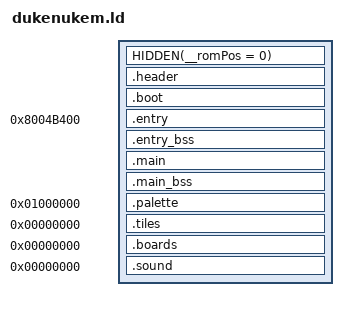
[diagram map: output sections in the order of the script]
SECTIONS
{
    HIDDEN(__romPos = 0);
    header_ROM_START = __romPos;
    header_VRAM = ADDR(.header);
    .header : AT(header_ROM_START) SUBALIGN(16)
    {
        FILL(0x00000000);
        header_DATA_START = .;
        build/header.o(.data);
        header_DATA_END = .;
        header_DATA_SIZE = ABSOLUTE(header_DATA_END - header_DATA_START);
    }
    __romPos += SIZEOF(.header);
    header_ROM_END = __romPos;
    header_VRAM_END = .;

    boot_ROM_START = __romPos;
    boot_VRAM = ADDR(.boot);
    .boot : AT(boot_ROM_START) SUBALIGN(16)
    {
        FILL(0x00000000);
        boot_DATA_START = .;
        build/assets/boot.o(.data);
        boot_DATA_END = .;
        boot_DATA_SIZE = ABSOLUTE(boot_DATA_END - boot_DATA_START);
    }
    __romPos += SIZEOF(.boot);
    boot_ROM_END = __romPos;
    boot_VRAM_END = .;

    entry_ROM_START = __romPos;
    entry_VRAM = ADDR(.entry);
    .entry 0x8004B400 : AT(entry_ROM_START) SUBALIGN(16)
    {
        FILL(0x00000000);
        entry_TEXT_START = .;
        build/src/entry.o(.text);
        . = ALIGN(., 16);
        entry_TEXT_END = .;
        entry_TEXT_SIZE = ABSOLUTE(entry_TEXT_END - entry_TEXT_START);
        entry_DATA_START = .;
        build/src/entry.o(.data);
        . = ALIGN(., 16);
        entry_DATA_END = .;
        entry_DATA_SIZE = ABSOLUTE(entry_DATA_END - entry_DATA_START);
        entry_RODATA_START = .;
        build/src/entry.o(.rodata);
        . = ALIGN(., 16);
        entry_RODATA_END = .;
        entry_RODATA_SIZE = ABSOLUTE(entry_RODATA_END - entry_RODATA_START);
    }
    entry_bss_VRAM = ADDR(.entry_bss);
    .entry_bss (NOLOAD) : SUBALIGN(16)
    {
        FILL(0x00000000);
        entry_BSS_START = .;
        build/src/entry.o(.bss);
        . = ALIGN(., 16);
        entry_BSS_END = .;
        entry_BSS_SIZE = ABSOLUTE(entry_BSS_END - entry_BSS_START);
    }
    __romPos += SIZEOF(.entry);
    __romPos = ALIGN(__romPos, 16);
    . = ALIGN(., 16);
    entry_ROM_END = __romPos;
    entry_VRAM_END = .;

    main_ROM_START = __romPos;
    main_VRAM = ADDR(.main);
    .main entry_VRAM_END : AT(main_ROM_START) SUBALIGN(16)
    {
        FILL(0x00000000);
        main_TEXT_START = .;
        build/src/main.o(.text);
        build/src/sched.o(.text);
        build/asm/control.o(.text);
        build/asm/game1.o(.text);
        build/asm/control2.o(.text);
        build/asm/game2.o(.text);
        build/asm/logo.o(.text);
        build/asm/boss2.o(.text);
        build/asm/sound1.o(.text);
        build/asm/sound2.o(.text);
        build/src/rend1.o(.text);
        build/asm/rend2.o(.text);
        build/src/getangle.o(.text);
        build/src/draw.o(.text);
        build/src/tileinfo.o(.text);
        build/src/rnc.o(.text);
        build/src/display1.o(.text);
        build/src/cache1d.o(.text);
        build/src/display2.o(.text);
        build/src/actors1.o(.text);
        build/src/actors2.o(.text);
        build/src/actors3.o(.text);
        build/src/gamedef.o(.text);
        build/src/script.o(.text);
        build/src/engine.o(.text);
        build/src/game3.o(.text);
        build/src/game4.o(.text);
        build/src/player1.o(.text);
        build/src/player2.o(.text);
        build/src/player3.o(.text);
        build/src/premap.o(.text);
        build/src/sector.o(.text);
        build/src/board.o(.text);
        build/src/tile.o(.text);
        build/src/tables.o(.text);
        build/src/dukebot.o(.text);
        build/asm/menues.o(.text);
        build/src/libultra/io/viblack.o(.text);
        build/src/libultra/os/initialize.o(.text);
        build/src/libultra/os/createthread.o(.text);
        build/src/libultra/os/startthread.o(.text);
        build/src/libultra/io/pimgr.o(.text);
        build/src/libultra/os/setthreadpri.o(.text);
        build/asm/libultra/os/writebackdcacheall.o(.text);
        build/src/libultra/io/pigetstat.o(.text);
        build/src/libultra/io/pidma.o(.text);
        build/src/libultra/os/recvmesg.o(.text);
        build/src/libultra/os/gettime.o(.text);
        build/src/libultra/os/sendmesg.o(.text);
        build/src/libultra/os/createmesgqueue.o(.text);
        build/src/libultra/libc/ll.o(.text);
        build/src/libultra/io/visetyscale.o(.text);
        build/src/libultra/io/vimgr.o(.text);
        build/src/libultra/io/vitbl.o(.text);
        build/asm/libultra/unk1.o(.text);
        build/src/libultra/io/visetmode.o(.text);
        build/src/libultra/io/visetspecial.o(.text);
        build/src/libultra/os/seteventmesg.o(.text);
        build/src/libultra/io/visetevent.o(.text);
        build/asm/libultra/os/setintmask.o(.text);
        build/src/libultra/io/sptaskyielded.o(.text);
        build/src/libultra/io/vigetcurrframebuf.o(.text);
        build/src/libultra/io/vigetnextframebuf.o(.text);
        build/src/libultra/io/viswapbuf.o(.text);
        build/src/libultra/io/sptask.o(.text);
        build/src/libultra/io/dpsetnextbuf.o(.text);
        build/src/libultra/io/sptaskyield.o(.text);
        build/src/libultra/io/contreaddata.o(.text);
        build/src/libultra/io/controller.o(.text);
        build/src/libultra/io/pfsinitpak.o(.text);
        build/src/libultra/io/pfsnumfiles.o(.text);
        build/src/libultra/io/pfsfreeblocks.o(.text);
        build/src/libultra/io/motor.o(.text);
        build/src/libultra/gu/translate.o(.text);
        build/src/libultra/gu/scale.o(.text);
        build/src/libultra/libc/sprintf.o(.text);
        build/src/libultra/libc/string.o(.text);
        build/src/libultra/io/pfsfilestate.o(.text);
        build/src/libultra/os/yieldthread.o(.text);
        build/src/libultra/io/pfsdeletefile.o(.text);
        build/src/libultra/io/pfsallocatefile.o(.text);
        build/src/libultra/io/pfsreadwritefile.o(.text);
        build/src/libultra/io/pfssearchfile.o(.text);
        build/src/libultra/io/pfsrepairid.o(.text);
        build/src/libultra/gu/rotate.o(.text);
        build/src/libultra/os/virtualtophysical.o(.text);
        build/src/libultra/audio/sl.o(.text);
        build/src/libultra/audio/heapalloc.o(.text);
        build/src/libultra/audio/heapinit.o(.text);
        build/src/libultra/io/aisetfreq.o(.text);
        build/src/libultra/audio/sndplayer.o(.text);
        build/src/libultra/audio/bnkf.o(.text);
        build/src/libultra/audio/sndpallocate.o(.text);
        build/src/libultra/audio/csplayer.o(.text);
        build/src/libultra/audio/seqpsetbank.o(.text);
        build/src/libultra/audio/cspsetvol.o(.text);
        build/src/libultra/audio/sndpsetsound.o(.text);
        build/src/libultra/audio/sndpgetstate.o(.text);
        build/src/libultra/audio/sndpsetpitch.o(.text);
        build/src/libultra/audio/sndpsetpan.o(.text);
        build/src/libultra/audio/sndpsetvol.o(.text);
        build/src/libultra/audio/sndpplay.o(.text);
        build/src/libultra/audio/cspstop.o(.text);
        build/src/libultra/audio/cseq.o(.text);
        build/src/libultra/audio/cspsetseq.o(.text);
        build/src/libultra/audio/cspplay.o(.text);
        build/src/libultra/audio/sndpstop.o(.text);
        build/src/libultra/audio/synthesizer.o(.text);
        build/src/libultra/io/aisetnextbuf.o(.text);
        build/src/libultra/gu/sinf.o(.text);
        build/src/libultra/gu/cosf.o(.text);
        build/src/libultra/libc/llcvt.o(.text);
        build/src/libultra/gu/perspective.o(.text);
        build/src/libultra/gu/lookat.o(.text);
        build/src/libultra/gu/lookatref.o(.text);
        build/src/libultra/gu/mtxcatf.o(.text);
        build/asm/libultra/gu/sqrtf.o(.text);
        build/asm/libultra/os/interrupt.o(.text);
        build/src/libultra/io/vi.o(.text);
        build/asm/libultra/os/setsr.o(.text);
        build/asm/libultra/os/getsr.o(.text);
        build/asm/libultra/os/setfpccsr.o(.text);
        build/src/libultra/io/sirawread.o(.text);
        build/src/libultra/io/sirawwrite.o(.text);
        build/asm/libultra/os/exceptasm.o(.text);
        build/asm/libultra/os/writebackdcache.o(.text);
        build/asm/libultra/os/invalicache.o(.text);
        build/asm/libultra/os/maptlbrdb.o(.text);
        build/src/libultra/io/pirawread.o(.text);
        build/asm/libultra/libc/bzero.o(.text);
        build/src/libultra/os/thread.o(.text);
        build/src/libultra/io/cartrominit.o(.text);
        build/src/libultra/io/leodiskinit.o(.text);
        build/src/libultra/io/piacs.o(.text);
        build/src/libultra/os/getthreadpri.o(.text);
        build/src/libultra/io/pirawdma.o(.text);
        build/src/libultra/io/epirawdma.o(.text);
        build/src/libultra/io/devmgr.o(.text);
        build/src/libultra/os/jammesg.o(.text);
        build/src/libultra/io/pigetcmdq.o(.text);
        build/asm/libultra/os/getcount.o(.text);
        build/src/libultra/os/timerintr.o(.text);
        build/src/libultra/io/vigetcurrcontext.o(.text);
        build/src/libultra/io/viswapcontext.o(.text);
        build/src/libultra/io/spgetstat.o(.text);
        build/asm/libultra/libc/bcopy.o(.text);
        build/src/libultra/io/spsetstat.o(.text);
        build/src/libultra/io/spsetpc.o(.text);
        build/src/libultra/io/sprawdma.o(.text);
        build/src/libultra/io/sp.o(.text);
        build/src/libultra/io/dp.o(.text);
        build/src/libultra/io/siacs.o(.text);
        build/src/libultra/io/sirawdma.o(.text);
        build/src/libultra/os/settimer.o(.text);
        build/src/libultra/io/pfsgetstatus.o(.text);
        build/src/libultra/io/contpfs.o(.text);
        build/src/libultra/io/contramread.o(.text);
        build/src/libultra/io/pfschecker.o(.text);
        build/src/libultra/io/pfsisplug.o(.text);
        build/src/libultra/io/crc.o(.text);
        build/src/libultra/io/contramwrite.o(.text);
        build/src/libultra/gu/mtxutil.o(.text);
        build/src/libultra/libc/xprintf.o(.text);
        build/src/libultra/gu/normalize.o(.text);
        build/asm/libultra/os/probetlb.o(.text);
        build/src/libultra/audio/syndelete.o(.text);
        build/src/libultra/audio/event.o(.text);
        build/src/libultra/audio/synaddplayer.o(.text);
        build/src/libultra/audio/synallocvoice.o(.text);
        build/src/libultra/audio/synstartvoice.o(.text);
        build/src/libultra/audio/synsetpan.o(.text);
        build/src/libultra/audio/synsetvol.o(.text);
        build/src/libultra/audio/synsetpitch.o(.text);
        build/src/libultra/audio/synsetfxmix.o(.text);
        build/src/libultra/audio/synstopvoice.o(.text);
        build/src/libultra/audio/synfreevoice.o(.text);
        build/src/libultra/audio/seqplayer.o(.text);
        build/src/libultra/audio/cents2ratio.o(.text);
        build/src/libultra/audio/synstartvoiceparam.o(.text);
        build/src/libultra/audio/drvrNew.o(.text);
        build/src/libultra/audio/synallocfx.o(.text);
        build/src/libultra/audio/mainbus.o(.text);
        build/src/libultra/audio/load.o(.text);
        build/src/libultra/audio/resample.o(.text);
        build/src/libultra/audio/env.o(.text);
        build/src/libultra/audio/auxbus.o(.text);
        build/src/libultra/audio/save.o(.text);
        build/src/libultra/io/ai.o(.text);
        build/src/libultra/io/si.o(.text);
        build/src/libultra/os/kdebugserver.o(.text);
        build/src/libultra/io/leointerrupt.o(.text);
        build/src/libultra/os/destroythread.o(.text);
        build/src/libultra/os/resetglobalintmask.o(.text);
        build/src/libultra/io/epirawwrite.o(.text);
        build/src/libultra/io/epirawread.o(.text);
        build/src/libultra/os/setglobalintmask.o(.text);
        build/asm/libultra/os/setcompare.o(.text);
        build/asm/libultra/os/invaldcache.o(.text);
        build/src/libultra/io/vimodepallan1.o(.text);
        build/src/libultra/io/vimodempallan1.o(.text);
        build/src/libultra/io/vimodentsclan1.o(.text);
        build/src/libultra/libc/xlitob.o(.text);
        build/src/libultra/libc/xldtob.o(.text);
        build/src/libultra/audio/copy.o(.text);
        build/src/libultra/audio/seq.o(.text);
        build/src/libultra/audio/synsetpriority.o(.text);
        build/src/libultra/audio/filter.o(.text);
        build/src/libultra/audio/reverb.o(.text);
        build/src/libultra/libc/ldiv.o(.text);
        build/data/ucode/boot.o(.text);
        build/data/ucode/rdp.o(.text);
        build/data/ucode/asp.o(.text);
        . = ALIGN(., 16);
        main_TEXT_END = .;
        main_TEXT_SIZE = ABSOLUTE(main_TEXT_END - main_TEXT_START);
        main_DATA_START = .;
        build/src/main.o(.data);
        build/src/sched.o(.data);
        build/data/asm/control.data.o(.data);
        build/data/asm/game1.data.o(.data);
        build/data/asm/control2.data.o(.data);
        build/data/asm/game2.data.o(.data);
        build/data/asm/logo.data.o(.data);
        build/data/asm/boss2.data.o(.data);
        build/data/asm/sound1.data.o(.data);
        build/data/asm/sound2.data.o(.data);
        build/data/src/rend1.data.o(.data);
        build/data/asm/rend2.data.o(.data);
        build/src/getangle.o(.data);
        build/src/draw.o(.data);
        build/src/tileinfo.o(.data);
        build/src/rnc.o(.data);
        build/src/display1.o(.data);
        build/src/cache1d.o(.data);
        build/src/display2.o(.data);
        build/src/actors1.o(.data);
        build/src/actors2.o(.data);
        build/src/actors3.o(.data);
        build/src/gamedef.o(.data);
        build/src/script.o(.data);
        build/src/engine.o(.data);
        build/src/game3.o(.data);
        build/src/game4.o(.data);
        build/src/player1.o(.data);
        build/src/player2.o(.data);
        build/src/player3.o(.data);
        build/src/premap.o(.data);
        build/src/sector.o(.data);
        build/src/board.o(.data);
        build/src/tile.o(.data);
        build/src/tables.o(.data);
        build/src/dukebot.o(.data);
        build/data/asm/menues.data.o(.data);
        build/src/libultra/io/viblack.o(.data);
        build/data/asm/global.data.o(.data);
        build/src/libultra/os/initialize.o(.data);
        build/src/libultra/os/createthread.o(.data);
        build/src/libultra/os/startthread.o(.data);
        build/src/libultra/io/pimgr.o(.data);
        build/src/libultra/os/setthreadpri.o(.data);
        build/asm/libultra/os/writebackdcacheall.o(.data);
        build/src/libultra/io/pigetstat.o(.data);
        build/src/libultra/io/pidma.o(.data);
        build/src/libultra/os/recvmesg.o(.data);
        build/src/libultra/os/gettime.o(.data);
        build/src/libultra/os/sendmesg.o(.data);
        build/src/libultra/os/createmesgqueue.o(.data);
        build/src/libultra/libc/ll.o(.data);
        build/src/libultra/io/visetyscale.o(.data);
        build/src/libultra/io/vimgr.o(.data);
        build/src/libultra/io/vitbl.o(.data);
        build/asm/libultra/unk1.o(.data);
        build/src/libultra/io/visetmode.o(.data);
        build/src/libultra/io/visetspecial.o(.data);
        build/src/libultra/os/seteventmesg.o(.data);
        build/src/libultra/io/visetevent.o(.data);
        build/asm/libultra/os/setintmask.o(.data);
        build/src/libultra/io/sptaskyielded.o(.data);
        build/src/libultra/io/vigetcurrframebuf.o(.data);
        build/src/libultra/io/vigetnextframebuf.o(.data);
        build/src/libultra/io/viswapbuf.o(.data);
        build/src/libultra/io/sptask.o(.data);
        build/src/libultra/io/dpsetnextbuf.o(.data);
        build/src/libultra/io/sptaskyield.o(.data);
        build/src/libultra/io/contreaddata.o(.data);
        build/src/libultra/io/controller.o(.data);
        build/src/libultra/io/pfsinitpak.o(.data);
        build/src/libultra/io/pfsnumfiles.o(.data);
        build/src/libultra/io/pfsfreeblocks.o(.data);
        build/src/libultra/io/motor.o(.data);
        build/src/libultra/gu/translate.o(.data);
        build/src/libultra/gu/scale.o(.data);
        build/src/libultra/libc/sprintf.o(.data);
        build/src/libultra/libc/string.o(.data);
        build/src/libultra/io/pfsfilestate.o(.data);
        build/src/libultra/os/yieldthread.o(.data);
        build/src/libultra/io/pfsdeletefile.o(.data);
        build/src/libultra/io/pfsallocatefile.o(.data);
        build/src/libultra/io/pfsreadwritefile.o(.data);
        build/src/libultra/io/pfssearchfile.o(.data);
        build/src/libultra/io/pfsrepairid.o(.data);
        build/src/libultra/gu/rotate.o(.data);
        build/src/libultra/os/virtualtophysical.o(.data);
        build/src/libultra/audio/sl.o(.data);
        build/src/libultra/audio/heapalloc.o(.data);
        build/src/libultra/audio/heapinit.o(.data);
        build/src/libultra/io/aisetfreq.o(.data);
        build/src/libultra/audio/sndplayer.o(.data);
        build/src/libultra/audio/bnkf.o(.data);
        build/src/libultra/audio/sndpallocate.o(.data);
        build/src/libultra/audio/csplayer.o(.data);
        build/src/libultra/audio/seqpsetbank.o(.data);
        build/src/libultra/audio/cspsetvol.o(.data);
        build/src/libultra/audio/sndpsetsound.o(.data);
        build/src/libultra/audio/sndpgetstate.o(.data);
        build/src/libultra/audio/sndpsetpitch.o(.data);
        build/src/libultra/audio/sndpsetpan.o(.data);
        build/src/libultra/audio/sndpsetvol.o(.data);
        build/src/libultra/audio/sndpplay.o(.data);
        build/src/libultra/audio/cspstop.o(.data);
        build/src/libultra/audio/cseq.o(.data);
        build/src/libultra/audio/cspsetseq.o(.data);
        build/src/libultra/audio/cspplay.o(.data);
        build/src/libultra/audio/sndpstop.o(.data);
        build/src/libultra/audio/synthesizer.o(.data);
        build/src/libultra/io/aisetnextbuf.o(.data);
        build/src/libultra/gu/sinf.o(.data);
        build/src/libultra/gu/cosf.o(.data);
        build/src/libultra/libc/llcvt.o(.data);
        build/src/libultra/gu/perspective.o(.data);
        build/src/libultra/gu/lookat.o(.data);
        build/src/libultra/gu/lookatref.o(.data);
        build/src/libultra/gu/mtxcatf.o(.data);
        build/asm/libultra/gu/sqrtf.o(.data);
        build/asm/libultra/os/interrupt.o(.data);
        build/src/libultra/io/vi.o(.data);
        build/asm/libultra/os/setsr.o(.data);
        build/asm/libultra/os/getsr.o(.data);
        build/asm/libultra/os/setfpccsr.o(.data);
        build/src/libultra/io/sirawread.o(.data);
        build/src/libultra/io/sirawwrite.o(.data);
        build/data/asm/libultra/os/exceptasm.data.o(.data);
        build/asm/libultra/os/writebackdcache.o(.data);
        build/asm/libultra/os/invalicache.o(.data);
        build/asm/libultra/os/maptlbrdb.o(.data);
        build/src/libultra/io/pirawread.o(.data);
        build/asm/libultra/libc/bzero.o(.data);
        build/src/libultra/os/thread.o(.data);
        build/src/libultra/io/cartrominit.o(.data);
        build/src/libultra/io/leodiskinit.o(.data);
        build/src/libultra/io/piacs.o(.data);
        build/src/libultra/os/getthreadpri.o(.data);
        build/src/libultra/io/pirawdma.o(.data);
        build/src/libultra/io/epirawdma.o(.data);
        build/src/libultra/io/devmgr.o(.data);
        build/src/libultra/os/jammesg.o(.data);
        build/src/libultra/io/pigetcmdq.o(.data);
        build/asm/libultra/os/getcount.o(.data);
        build/src/libultra/os/timerintr.o(.data);
        build/src/libultra/io/vigetcurrcontext.o(.data);
        build/src/libultra/io/viswapcontext.o(.data);
        build/src/libultra/io/spgetstat.o(.data);
        build/asm/libultra/libc/bcopy.o(.data);
        build/src/libultra/io/spsetstat.o(.data);
        build/src/libultra/io/spsetpc.o(.data);
        build/src/libultra/io/sprawdma.o(.data);
        build/src/libultra/io/sp.o(.data);
        build/src/libultra/io/dp.o(.data);
        build/src/libultra/io/siacs.o(.data);
        build/src/libultra/io/sirawdma.o(.data);
        build/src/libultra/os/settimer.o(.data);
        build/src/libultra/io/pfsgetstatus.o(.data);
        build/src/libultra/io/contpfs.o(.data);
        build/src/libultra/io/contramread.o(.data);
        build/src/libultra/io/pfschecker.o(.data);
        build/src/libultra/io/pfsisplug.o(.data);
        build/src/libultra/io/crc.o(.data);
        build/src/libultra/io/contramwrite.o(.data);
        build/src/libultra/gu/mtxutil.o(.data);
        build/src/libultra/libc/xprintf.o(.data);
        build/src/libultra/gu/normalize.o(.data);
        build/asm/libultra/os/probetlb.o(.data);
        build/src/libultra/audio/syndelete.o(.data);
        build/src/libultra/audio/event.o(.data);
        build/src/libultra/audio/synaddplayer.o(.data);
        build/src/libultra/audio/synallocvoice.o(.data);
        build/src/libultra/audio/synstartvoice.o(.data);
        build/src/libultra/audio/synsetpan.o(.data);
        build/src/libultra/audio/synsetvol.o(.data);
        build/src/libultra/audio/synsetpitch.o(.data);
        build/src/libultra/audio/synsetfxmix.o(.data);
        build/src/libultra/audio/synstopvoice.o(.data);
        build/src/libultra/audio/synfreevoice.o(.data);
        build/src/libultra/audio/seqplayer.o(.data);
        build/src/libultra/audio/cents2ratio.o(.data);
        build/src/libultra/audio/synstartvoiceparam.o(.data);
        build/src/libultra/audio/drvrNew.o(.data);
        build/src/libultra/audio/synallocfx.o(.data);
        build/src/libultra/audio/mainbus.o(.data);
        build/src/libultra/audio/load.o(.data);
        build/src/libultra/audio/resample.o(.data);
        build/src/libultra/audio/env.o(.data);
        build/src/libultra/audio/auxbus.o(.data);
        build/src/libultra/audio/save.o(.data);
        build/src/libultra/io/ai.o(.data);
        build/src/libultra/io/si.o(.data);
        build/src/libultra/os/kdebugserver.o(.data);
        build/src/libultra/io/leointerrupt.o(.data);
        build/src/libultra/os/destroythread.o(.data);
        build/src/libultra/os/resetglobalintmask.o(.data);
        build/src/libultra/io/epirawwrite.o(.data);
        build/src/libultra/io/epirawread.o(.data);
        build/src/libultra/os/setglobalintmask.o(.data);
        build/asm/libultra/os/setcompare.o(.data);
        build/asm/libultra/os/invaldcache.o(.data);
        build/src/libultra/io/vimodepallan1.o(.data);
        build/src/libultra/io/vimodempallan1.o(.data);
        build/src/libultra/io/vimodentsclan1.o(.data);
        build/src/libultra/libc/xlitob.o(.data);
        build/src/libultra/libc/xldtob.o(.data);
        build/src/libultra/audio/copy.o(.data);
        build/src/libultra/audio/seq.o(.data);
        build/src/libultra/audio/synsetpriority.o(.data);
        build/src/libultra/audio/filter.o(.data);
        build/src/libultra/audio/reverb.o(.data);
        build/src/libultra/libc/ldiv.o(.data);
        build/data/ucode/boot.o(.data);
        build/data/ucode/rdp.o(.data);
        build/data/ucode/asp.o(.data);
        . = ALIGN(., 16);
        main_DATA_END = .;
        main_DATA_SIZE = ABSOLUTE(main_DATA_END - main_DATA_START);
        main_RODATA_START = .;
        build/src/main.o(.rodata);
        build/src/sched.o(.rodata);
        build/data/asm/control.rodata.o(.rodata);
        build/data/asm/game1.rodata.o(.rodata);
        build/data/asm/control2.rodata.o(.rodata);
        build/data/asm/game2.rodata.o(.rodata);
        build/data/asm/logo.rodata.o(.rodata);
        build/data/asm/boss2.rodata.o(.rodata);
        build/data/asm/sound1.rodata.o(.rodata);
        build/asm/sound2.o(.rodata);
        build/src/rend1.o(.rodata);
        build/data/asm/rend2.rodata.o(.rodata);
        build/src/getangle.o(.rodata);
        build/src/draw.o(.rodata);
        build/src/tileinfo.o(.rodata);
        build/src/rnc.o(.rodata);
        build/src/display1.o(.rodata);
        build/src/cache1d.o(.rodata);
        build/src/display2.o(.rodata);
        build/src/actors1.o(.rodata);
        build/src/actors2.o(.rodata);
        build/src/actors3.o(.rodata);
        build/src/gamedef.o(.rodata);
        build/src/script.o(.rodata);
        build/src/engine.o(.rodata);
        build/src/game3.o(.rodata);
        build/src/game4.o(.rodata);
        build/src/player1.o(.rodata);
        build/src/player2.o(.rodata);
        build/src/player3.o(.rodata);
        build/src/premap.o(.rodata);
        build/src/sector.o(.rodata);
        build/src/board.o(.rodata);
        build/src/tile.o(.rodata);
        build/src/tables.o(.rodata);
        build/src/dukebot.o(.rodata);
        build/data/asm/menues.rodata.o(.rodata);
        build/src/libultra/io/viblack.o(.rodata);
        build/src/libultra/os/initialize.o(.rodata);
        build/src/libultra/os/createthread.o(.rodata);
        build/src/libultra/os/startthread.o(.rodata);
        build/src/libultra/io/pimgr.o(.rodata);
        build/src/libultra/os/setthreadpri.o(.rodata);
        build/asm/libultra/os/writebackdcacheall.o(.rodata);
        build/src/libultra/io/pigetstat.o(.rodata);
        build/src/libultra/io/pidma.o(.rodata);
        build/src/libultra/os/recvmesg.o(.rodata);
        build/src/libultra/os/gettime.o(.rodata);
        build/src/libultra/os/sendmesg.o(.rodata);
        build/src/libultra/os/createmesgqueue.o(.rodata);
        build/src/libultra/libc/ll.o(.rodata);
        build/src/libultra/io/visetyscale.o(.rodata);
        build/src/libultra/io/vimgr.o(.rodata);
        build/src/libultra/io/vitbl.o(.rodata);
        build/asm/libultra/unk1.o(.rodata);
        build/src/libultra/io/visetmode.o(.rodata);
        build/src/libultra/io/visetspecial.o(.rodata);
        build/src/libultra/os/seteventmesg.o(.rodata);
        build/src/libultra/io/visetevent.o(.rodata);
        build/data/asm/libultra/os/setintmask.rodata.o(.rodata);
        build/src/libultra/io/sptaskyielded.o(.rodata);
        build/src/libultra/io/vigetcurrframebuf.o(.rodata);
        build/src/libultra/io/vigetnextframebuf.o(.rodata);
        build/src/libultra/io/viswapbuf.o(.rodata);
        build/src/libultra/io/sptask.o(.rodata);
        build/src/libultra/io/dpsetnextbuf.o(.rodata);
        build/src/libultra/io/sptaskyield.o(.rodata);
        build/src/libultra/io/contreaddata.o(.rodata);
        build/src/libultra/io/controller.o(.rodata);
        build/src/libultra/io/pfsinitpak.o(.rodata);
        build/src/libultra/io/pfsnumfiles.o(.rodata);
        build/src/libultra/io/pfsfreeblocks.o(.rodata);
        build/src/libultra/io/motor.o(.rodata);
        build/src/libultra/gu/translate.o(.rodata);
        build/src/libultra/gu/scale.o(.rodata);
        build/src/libultra/libc/sprintf.o(.rodata);
        build/src/libultra/libc/string.o(.rodata);
        build/src/libultra/io/pfsfilestate.o(.rodata);
        build/src/libultra/os/yieldthread.o(.rodata);
        build/src/libultra/io/pfsdeletefile.o(.rodata);
        build/src/libultra/io/pfsallocatefile.o(.rodata);
        build/src/libultra/io/pfsreadwritefile.o(.rodata);
        build/src/libultra/io/pfssearchfile.o(.rodata);
        build/src/libultra/io/pfsrepairid.o(.rodata);
        build/src/libultra/gu/rotate.o(.rodata);
        build/src/libultra/os/virtualtophysical.o(.rodata);
        build/src/libultra/audio/sl.o(.rodata);
        build/src/libultra/audio/heapalloc.o(.rodata);
        build/src/libultra/audio/heapinit.o(.rodata);
        build/src/libultra/io/aisetfreq.o(.rodata);
        build/src/libultra/audio/sndplayer.o(.rodata);
        build/src/libultra/audio/bnkf.o(.rodata);
        build/src/libultra/audio/sndpallocate.o(.rodata);
        build/src/libultra/audio/csplayer.o(.rodata);
        build/src/libultra/audio/seqpsetbank.o(.rodata);
        build/src/libultra/audio/cspsetvol.o(.rodata);
        build/src/libultra/audio/sndpsetsound.o(.rodata);
        build/src/libultra/audio/sndpgetstate.o(.rodata);
        build/src/libultra/audio/sndpsetpitch.o(.rodata);
        build/src/libultra/audio/sndpsetpan.o(.rodata);
        build/src/libultra/audio/sndpsetvol.o(.rodata);
        build/src/libultra/audio/sndpplay.o(.rodata);
        build/src/libultra/audio/cspstop.o(.rodata);
        build/src/libultra/audio/cseq.o(.rodata);
        build/src/libultra/audio/cspsetseq.o(.rodata);
        build/src/libultra/audio/cspplay.o(.rodata);
        build/src/libultra/audio/sndpstop.o(.rodata);
        build/src/libultra/audio/synthesizer.o(.rodata);
        build/src/libultra/io/aisetnextbuf.o(.rodata);
        build/src/libultra/gu/sinf.o(.rodata);
        build/src/libultra/gu/cosf.o(.rodata);
        build/src/libultra/libc/llcvt.o(.rodata);
        build/src/libultra/gu/perspective.o(.rodata);
        build/src/libultra/gu/lookat.o(.rodata);
        build/src/libultra/gu/lookatref.o(.rodata);
        build/src/libultra/gu/mtxcatf.o(.rodata);
        build/asm/libultra/gu/sqrtf.o(.rodata);
        build/asm/libultra/os/interrupt.o(.rodata);
        build/src/libultra/io/vi.o(.rodata);
        build/asm/libultra/os/setsr.o(.rodata);
        build/asm/libultra/os/getsr.o(.rodata);
        build/asm/libultra/os/setfpccsr.o(.rodata);
        build/src/libultra/io/sirawread.o(.rodata);
        build/src/libultra/io/sirawwrite.o(.rodata);
        build/data/asm/libultra/os/exceptasm.rodata.o(.rodata);
        build/asm/libultra/os/writebackdcache.o(.rodata);
        build/asm/libultra/os/invalicache.o(.rodata);
        build/asm/libultra/os/maptlbrdb.o(.rodata);
        build/src/libultra/io/pirawread.o(.rodata);
        build/asm/libultra/libc/bzero.o(.rodata);
        build/src/libultra/os/thread.o(.rodata);
        build/src/libultra/io/cartrominit.o(.rodata);
        build/src/libultra/io/leodiskinit.o(.rodata);
        build/src/libultra/io/piacs.o(.rodata);
        build/src/libultra/os/getthreadpri.o(.rodata);
        build/src/libultra/io/pirawdma.o(.rodata);
        build/src/libultra/io/epirawdma.o(.rodata);
        build/src/libultra/io/devmgr.o(.rodata);
        build/src/libultra/os/jammesg.o(.rodata);
        build/src/libultra/io/pigetcmdq.o(.rodata);
        build/asm/libultra/os/getcount.o(.rodata);
        build/src/libultra/os/timerintr.o(.rodata);
        build/src/libultra/io/vigetcurrcontext.o(.rodata);
        build/src/libultra/io/viswapcontext.o(.rodata);
        build/src/libultra/io/spgetstat.o(.rodata);
        build/asm/libultra/libc/bcopy.o(.rodata);
        build/src/libultra/io/spsetstat.o(.rodata);
        build/src/libultra/io/spsetpc.o(.rodata);
        build/src/libultra/io/sprawdma.o(.rodata);
        build/src/libultra/io/sp.o(.rodata);
        build/src/libultra/io/dp.o(.rodata);
        build/src/libultra/io/siacs.o(.rodata);
        build/src/libultra/io/sirawdma.o(.rodata);
        build/src/libultra/os/settimer.o(.rodata);
        build/src/libultra/io/pfsgetstatus.o(.rodata);
        build/src/libultra/io/contpfs.o(.rodata);
        build/src/libultra/io/contramread.o(.rodata);
        build/src/libultra/io/pfschecker.o(.rodata);
        build/src/libultra/io/pfsisplug.o(.rodata);
        build/src/libultra/io/crc.o(.rodata);
        build/src/libultra/io/contramwrite.o(.rodata);
        build/src/libultra/gu/mtxutil.o(.rodata);
        build/src/libultra/libc/xprintf.o(.rodata);
        build/src/libultra/gu/normalize.o(.rodata);
        build/asm/libultra/os/probetlb.o(.rodata);
        build/src/libultra/audio/syndelete.o(.rodata);
        build/src/libultra/audio/event.o(.rodata);
        build/src/libultra/audio/synaddplayer.o(.rodata);
        build/src/libultra/audio/synallocvoice.o(.rodata);
        build/src/libultra/audio/synstartvoice.o(.rodata);
        build/src/libultra/audio/synsetpan.o(.rodata);
        build/src/libultra/audio/synsetvol.o(.rodata);
        build/src/libultra/audio/synsetpitch.o(.rodata);
        build/src/libultra/audio/synsetfxmix.o(.rodata);
        build/src/libultra/audio/synstopvoice.o(.rodata);
        build/src/libultra/audio/synfreevoice.o(.rodata);
        build/src/libultra/audio/seqplayer.o(.rodata);
        build/src/libultra/audio/cents2ratio.o(.rodata);
        build/src/libultra/audio/synstartvoiceparam.o(.rodata);
        build/src/libultra/audio/drvrNew.o(.rodata);
        build/src/libultra/audio/synallocfx.o(.rodata);
        build/src/libultra/audio/mainbus.o(.rodata);
        build/src/libultra/audio/load.o(.rodata);
        build/src/libultra/audio/resample.o(.rodata);
        build/src/libultra/audio/env.o(.rodata);
        build/src/libultra/audio/auxbus.o(.rodata);
        build/src/libultra/audio/save.o(.rodata);
        build/src/libultra/io/ai.o(.rodata);
        build/src/libultra/io/si.o(.rodata);
        build/src/libultra/os/kdebugserver.o(.rodata);
        build/src/libultra/io/leointerrupt.o(.rodata);
        build/src/libultra/os/destroythread.o(.rodata);
        build/src/libultra/os/resetglobalintmask.o(.rodata);
        build/src/libultra/io/epirawwrite.o(.rodata);
        build/src/libultra/io/epirawread.o(.rodata);
        build/src/libultra/os/setglobalintmask.o(.rodata);
        build/asm/libultra/os/setcompare.o(.rodata);
        build/asm/libultra/os/invaldcache.o(.rodata);
        build/src/libultra/io/vimodepallan1.o(.rodata);
        build/src/libultra/io/vimodempallan1.o(.rodata);
        build/src/libultra/io/vimodentsclan1.o(.rodata);
        build/src/libultra/libc/xlitob.o(.rodata);
        build/data/asm/libultra/gu/libm_vals.rodata.o(.rodata);
        build/src/libultra/libc/xldtob.o(.rodata);
        build/src/libultra/audio/copy.o(.rodata);
        build/src/libultra/audio/seq.o(.rodata);
        build/src/libultra/audio/synsetpriority.o(.rodata);
        build/src/libultra/audio/filter.o(.rodata);
        build/src/libultra/audio/reverb.o(.rodata);
        build/src/libultra/libc/ldiv.o(.rodata);
        build/data/ucode/boot.o(.rodata);
        build/data/ucode/rdp.o(.rodata);
        build/data/ucode/asp.o(.rodata);
        build/data/ucode/rdp_data.o(.rodata);
        build/data/ucode/asp_data.o(.rodata);
        . = ALIGN(., 16);
        main_RODATA_END = .;
        main_RODATA_SIZE = ABSOLUTE(main_RODATA_END - main_RODATA_START);
    }
    main_bss_VRAM = ADDR(.main_bss);
    .main_bss (NOLOAD) : SUBALIGN(16)
    {
        FILL(0x00000000);
        main_BSS_START = .;
        build/src/main.o(.bss);
        build/src/sched.o(.bss);
        build/data/asm/control.bss.o(.bss);
        build/data/asm/game1.bss.o(.bss);
        build/data/asm/control2.bss.o(.bss);
        build/data/asm/game2.bss.o(.bss);
        build/asm/logo.o(.bss);
        build/data/asm/boss2.bss.o(.bss);
        build/data/asm/sound1.bss.o(.bss);
        build/asm/sound2.o(.bss);
        build/data/src/rend1.bss.o(.bss);
        build/data/asm/rend2.bss.o(.bss);
        build/src/getangle.o(.bss);
        build/src/draw.o(.bss);
        build/src/tileinfo.o(.bss);
        build/src/rnc.o(.bss);
        build/src/display1.o(.bss);
        build/src/cache1d.o(.bss);
        build/src/display2.o(.bss);
        build/src/actors1.o(.bss);
        build/src/actors2.o(.bss);
        build/src/actors3.o(.bss);
        build/src/gamedef.o(.bss);
        build/src/script.o(.bss);
        build/src/engine.o(.bss);
        build/src/game3.o(.bss);
        build/src/game4.o(.bss);
        build/src/player1.o(.bss);
        build/src/player2.o(.bss);
        build/src/player3.o(.bss);
        build/src/premap.o(.bss);
        build/src/sector.o(.bss);
        build/src/board.o(.bss);
        build/src/tile.o(.bss);
        build/src/tables.o(.bss);
        build/src/dukebot.o(.bss);
        build/data/asm/menues.bss.o(.bss);
        build/src/libultra/io/viblack.o(.bss);
        build/data/asm/global.bss.o(.bss);
        build/data/asm/global2.bss.o(.bss);
        build/src/libultra/os/initialize.o(.bss);
        build/src/libultra/os/createthread.o(.bss);
        build/src/libultra/os/startthread.o(.bss);
        build/src/libultra/io/pimgr.o(.bss);
        build/src/libultra/os/setthreadpri.o(.bss);
        build/asm/libultra/os/writebackdcacheall.o(.bss);
        build/src/libultra/io/pigetstat.o(.bss);
        build/src/libultra/io/pidma.o(.bss);
        build/src/libultra/os/recvmesg.o(.bss);
        build/src/libultra/os/gettime.o(.bss);
        build/src/libultra/os/sendmesg.o(.bss);
        build/src/libultra/os/createmesgqueue.o(.bss);
        build/src/libultra/libc/ll.o(.bss);
        build/src/libultra/io/visetyscale.o(.bss);
        build/src/libultra/io/vimgr.o(.bss);
        build/src/libultra/io/vitbl.o(.bss);
        build/asm/libultra/unk1.o(.bss);
        build/src/libultra/io/visetmode.o(.bss);
        build/src/libultra/io/visetspecial.o(.bss);
        build/src/libultra/os/seteventmesg.o(.bss);
        build/src/libultra/io/visetevent.o(.bss);
        build/asm/libultra/os/setintmask.o(.bss);
        build/src/libultra/io/sptaskyielded.o(.bss);
        build/src/libultra/io/vigetcurrframebuf.o(.bss);
        build/src/libultra/io/vigetnextframebuf.o(.bss);
        build/src/libultra/io/viswapbuf.o(.bss);
        build/src/libultra/io/sptask.o(.bss);
        build/src/libultra/io/dpsetnextbuf.o(.bss);
        build/src/libultra/io/sptaskyield.o(.bss);
        build/src/libultra/io/contreaddata.o(.bss);
        build/src/libultra/io/controller.o(.bss);
        build/src/libultra/io/pfsinitpak.o(.bss);
        build/src/libultra/io/pfsnumfiles.o(.bss);
        build/src/libultra/io/pfsfreeblocks.o(.bss);
        build/src/libultra/io/motor.o(.bss);
        build/src/libultra/gu/translate.o(.bss);
        build/src/libultra/gu/scale.o(.bss);
        build/src/libultra/libc/sprintf.o(.bss);
        build/src/libultra/libc/string.o(.bss);
        build/src/libultra/io/pfsfilestate.o(.bss);
        build/src/libultra/os/yieldthread.o(.bss);
        build/src/libultra/io/pfsdeletefile.o(.bss);
        build/src/libultra/io/pfsallocatefile.o(.bss);
        build/src/libultra/io/pfsreadwritefile.o(.bss);
        build/src/libultra/io/pfssearchfile.o(.bss);
        build/src/libultra/io/pfsrepairid.o(.bss);
        build/src/libultra/gu/rotate.o(.bss);
        build/src/libultra/os/virtualtophysical.o(.bss);
        build/src/libultra/audio/sl.o(.bss);
        build/src/libultra/audio/heapalloc.o(.bss);
        build/src/libultra/audio/heapinit.o(.bss);
        build/src/libultra/io/aisetfreq.o(.bss);
        build/src/libultra/audio/sndplayer.o(.bss);
        build/src/libultra/audio/bnkf.o(.bss);
        build/src/libultra/audio/sndpallocate.o(.bss);
        build/src/libultra/audio/csplayer.o(.bss);
        build/src/libultra/audio/seqpsetbank.o(.bss);
        build/src/libultra/audio/cspsetvol.o(.bss);
        build/src/libultra/audio/sndpsetsound.o(.bss);
        build/src/libultra/audio/sndpgetstate.o(.bss);
        build/src/libultra/audio/sndpsetpitch.o(.bss);
        build/src/libultra/audio/sndpsetpan.o(.bss);
        build/src/libultra/audio/sndpsetvol.o(.bss);
        build/src/libultra/audio/sndpplay.o(.bss);
        build/src/libultra/audio/cspstop.o(.bss);
        build/src/libultra/audio/cseq.o(.bss);
        build/src/libultra/audio/cspsetseq.o(.bss);
        build/src/libultra/audio/cspplay.o(.bss);
        build/src/libultra/audio/sndpstop.o(.bss);
        build/src/libultra/audio/synthesizer.o(.bss);
        build/src/libultra/io/aisetnextbuf.o(.bss);
        build/src/libultra/gu/sinf.o(.bss);
        build/src/libultra/gu/cosf.o(.bss);
        build/src/libultra/libc/llcvt.o(.bss);
        build/src/libultra/gu/perspective.o(.bss);
        build/src/libultra/gu/lookat.o(.bss);
        build/src/libultra/gu/lookatref.o(.bss);
        build/src/libultra/gu/mtxcatf.o(.bss);
        build/asm/libultra/gu/sqrtf.o(.bss);
        build/asm/libultra/os/interrupt.o(.bss);
        build/src/libultra/io/vi.o(.bss);
        build/asm/libultra/os/setsr.o(.bss);
        build/asm/libultra/os/getsr.o(.bss);
        build/asm/libultra/os/setfpccsr.o(.bss);
        build/src/libultra/io/sirawread.o(.bss);
        build/src/libultra/io/sirawwrite.o(.bss);
        build/asm/libultra/os/exceptasm.o(.bss);
        build/asm/libultra/os/writebackdcache.o(.bss);
        build/asm/libultra/os/invalicache.o(.bss);
        build/asm/libultra/os/maptlbrdb.o(.bss);
        build/src/libultra/io/pirawread.o(.bss);
        build/asm/libultra/libc/bzero.o(.bss);
        build/src/libultra/os/thread.o(.bss);
        build/src/libultra/io/cartrominit.o(.bss);
        build/src/libultra/io/leodiskinit.o(.bss);
        build/src/libultra/io/piacs.o(.bss);
        build/src/libultra/os/getthreadpri.o(.bss);
        build/src/libultra/io/pirawdma.o(.bss);
        build/src/libultra/io/epirawdma.o(.bss);
        build/src/libultra/io/devmgr.o(.bss);
        build/src/libultra/os/jammesg.o(.bss);
        build/src/libultra/io/pigetcmdq.o(.bss);
        build/asm/libultra/os/getcount.o(.bss);
        build/src/libultra/os/timerintr.o(.bss);
        build/src/libultra/io/vigetcurrcontext.o(.bss);
        build/src/libultra/io/viswapcontext.o(.bss);
        build/src/libultra/io/spgetstat.o(.bss);
        build/asm/libultra/libc/bcopy.o(.bss);
        build/src/libultra/io/spsetstat.o(.bss);
        build/src/libultra/io/spsetpc.o(.bss);
        build/src/libultra/io/sprawdma.o(.bss);
        build/src/libultra/io/sp.o(.bss);
        build/src/libultra/io/dp.o(.bss);
        build/src/libultra/io/siacs.o(.bss);
        build/src/libultra/io/sirawdma.o(.bss);
        build/src/libultra/os/settimer.o(.bss);
        build/src/libultra/io/pfsgetstatus.o(.bss);
        build/src/libultra/io/contpfs.o(.bss);
        build/src/libultra/io/contramread.o(.bss);
        build/src/libultra/io/pfschecker.o(.bss);
        build/src/libultra/io/pfsisplug.o(.bss);
        build/src/libultra/io/crc.o(.bss);
        build/src/libultra/io/contramwrite.o(.bss);
        build/src/libultra/gu/mtxutil.o(.bss);
        build/src/libultra/libc/xprintf.o(.bss);
        build/src/libultra/gu/normalize.o(.bss);
        build/asm/libultra/os/probetlb.o(.bss);
        build/src/libultra/audio/syndelete.o(.bss);
        build/src/libultra/audio/event.o(.bss);
        build/src/libultra/audio/synaddplayer.o(.bss);
        build/src/libultra/audio/synallocvoice.o(.bss);
        build/src/libultra/audio/synstartvoice.o(.bss);
        build/src/libultra/audio/synsetpan.o(.bss);
        build/src/libultra/audio/synsetvol.o(.bss);
        build/src/libultra/audio/synsetpitch.o(.bss);
        build/src/libultra/audio/synsetfxmix.o(.bss);
        build/src/libultra/audio/synstopvoice.o(.bss);
        build/src/libultra/audio/synfreevoice.o(.bss);
        build/src/libultra/audio/seqplayer.o(.bss);
        build/src/libultra/audio/cents2ratio.o(.bss);
        build/src/libultra/audio/synstartvoiceparam.o(.bss);
        build/src/libultra/audio/drvrNew.o(.bss);
        build/src/libultra/audio/synallocfx.o(.bss);
        build/src/libultra/audio/mainbus.o(.bss);
        build/src/libultra/audio/load.o(.bss);
        build/src/libultra/audio/resample.o(.bss);
        build/src/libultra/audio/env.o(.bss);
        build/src/libultra/audio/auxbus.o(.bss);
        build/src/libultra/audio/save.o(.bss);
        build/src/libultra/io/ai.o(.bss);
        build/src/libultra/io/si.o(.bss);
        build/src/libultra/os/kdebugserver.o(.bss);
        build/src/libultra/io/leointerrupt.o(.bss);
        build/src/libultra/os/destroythread.o(.bss);
        build/src/libultra/os/resetglobalintmask.o(.bss);
        build/src/libultra/io/epirawwrite.o(.bss);
        build/src/libultra/io/epirawread.o(.bss);
        build/src/libultra/os/setglobalintmask.o(.bss);
        build/asm/libultra/os/setcompare.o(.bss);
        build/asm/libultra/os/invaldcache.o(.bss);
        build/src/libultra/io/vimodepallan1.o(.bss);
        build/src/libultra/io/vimodempallan1.o(.bss);
        build/src/libultra/io/vimodentsclan1.o(.bss);
        build/src/libultra/libc/xlitob.o(.bss);
        build/src/libultra/libc/xldtob.o(.bss);
        build/src/libultra/audio/copy.o(.bss);
        build/src/libultra/audio/seq.o(.bss);
        build/src/libultra/audio/synsetpriority.o(.bss);
        build/src/libultra/audio/filter.o(.bss);
        build/src/libultra/audio/reverb.o(.bss);
        build/src/libultra/libc/ldiv.o(.bss);
        build/data/ucode/boot.o(.bss);
        build/data/ucode/rdp.o(.bss);
        build/data/ucode/asp.o(.bss);
        . = ALIGN(., 16);
        main_BSS_END = .;
        main_BSS_SIZE = ABSOLUTE(main_BSS_END - main_BSS_START);
    }
    __romPos += SIZEOF(.main);
    __romPos = ALIGN(__romPos, 16);
    . = ALIGN(., 16);
    main_ROM_END = __romPos;
    main_VRAM_END = .;

    palette_ROM_START = __romPos;
    palette_VRAM = ADDR(.palette);
    .palette 0x1000000 : AT(palette_ROM_START) SUBALIGN(16)
    {
        FILL(0x00000000);
        palette_DATA_START = .;
        build/assets/palette.o(.data);
        build/src/dlstatic.o(.data);
        . = ALIGN(., 16);
        palette_DATA_END = .;
        palette_DATA_SIZE = ABSOLUTE(palette_DATA_END - palette_DATA_START);
    }
    __romPos += SIZEOF(.palette);
    __romPos = ALIGN(__romPos, 16);
    . = ALIGN(., 16);
    palette_ROM_END = __romPos;
    palette_VRAM_END = .;

    tiles_ROM_START = __romPos;
    tiles_VRAM = ADDR(.tiles);
    .tiles 0x0 : AT(tiles_ROM_START) SUBALIGN(16)
    {
        FILL(0x00000000);
        tiles_DATA_START = .;
        build/assets/tileblob.o(.data);
        . = ALIGN(., 16);
        tiles_DATA_END = .;
        tiles_DATA_SIZE = ABSOLUTE(tiles_DATA_END - tiles_DATA_START);
    }
    __romPos += SIZEOF(.tiles);
    __romPos = ALIGN(__romPos, 16);
    . = ALIGN(., 16);
    tiles_ROM_END = __romPos;
    tiles_VRAM_END = .;

    boards_ROM_START = __romPos;
    boards_VRAM = ADDR(.boards);
    .boards 0x0 : AT(boards_ROM_START) SUBALIGN(16)
    {
        FILL(0x00000000);
        boards_DATA_START = .;
        build/assets/board01.o(.data);
        build/assets/board02.o(.data);
        build/assets/board03.o(.data);
        build/assets/board04.o(.data);
        build/assets/board06.o(.data);
        build/assets/board05.o(.data);
        build/assets/board07.o(.data);
        build/assets/board09.o(.data);
        build/assets/board10.o(.data);
        build/assets/board11.o(.data);
        build/assets/board12.o(.data);
        build/assets/board13.o(.data);
        build/assets/board14.o(.data);
        build/assets/board15.o(.data);
        build/assets/board16.o(.data);
        build/assets/board17.o(.data);
        build/assets/board18.o(.data);
        build/assets/board19.o(.data);
        build/assets/board20.o(.data);
        build/assets/board21.o(.data);
        build/assets/board22.o(.data);
        build/assets/board23.o(.data);
        build/assets/board24.o(.data);
        build/assets/board25.o(.data);
        build/assets/board26.o(.data);
        build/assets/board27.o(.data);
        build/assets/board28.o(.data);
        build/assets/board30.o(.data);
        build/assets/board08.o(.data);
        build/assets/board29.o(.data);
        build/assets/board31.o(.data);
        build/assets/board32.o(.data);
        build/assets/board33.o(.data);
        build/assets/board34.o(.data);
        . = ALIGN(., 16);
        boards_DATA_END = .;
        boards_DATA_SIZE = ABSOLUTE(boards_DATA_END - boards_DATA_START);
    }
    __romPos += SIZEOF(.boards);
    __romPos = ALIGN(__romPos, 16);
    . = ALIGN(., 16);
    boards_ROM_END = __romPos;
    boards_VRAM_END = .;

    sound_ROM_START = __romPos;
    sound_VRAM = ADDR(.sound);
    .sound 0x0 : AT(sound_ROM_START) SUBALIGN(16)
    {
        FILL(0x00000000);
        sound_DATA_START = .;
        build/assets/soundctl.o(.data);
        build/assets/soundtbl.o(.data);
        build/assets/musicseq.o(.data);
        build/assets/musicctl.o(.data);
        build/assets/musictbl.o(.data);
        . = ALIGN(., 16);
        sound_DATA_END = .;
        sound_DATA_SIZE = ABSOLUTE(sound_DATA_END - sound_DATA_START);
    }
    __romPos += SIZEOF(.sound);
    __romPos = ALIGN(__romPos, 16);
    . = ALIGN(., 16);
    sound_ROM_END = __romPos;
    sound_VRAM_END = .;

    /DISCARD/ :
    {
        *(*);
    }
}
